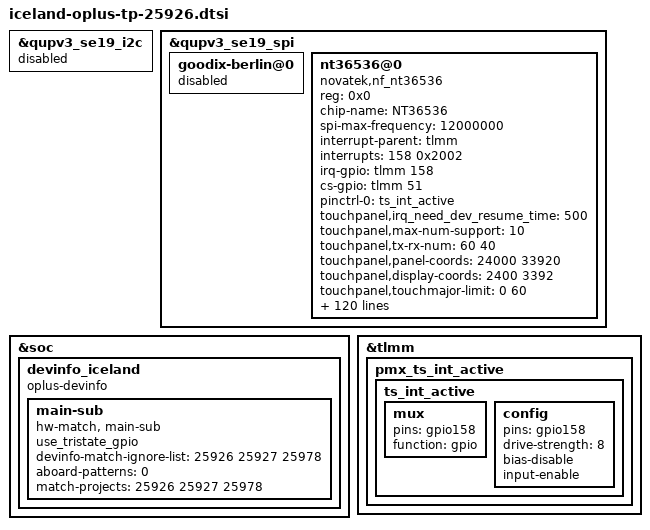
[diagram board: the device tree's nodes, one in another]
#include <dt-bindings/clock/qcom,gcc-sun.h>
#include <dt-bindings/clock/qcom,rpmh.h>
#include "iceland-oplus-tp_firmware_nt36536.dtsi"

&qupv3_se19_i2c {
	status = "disabled";
};
/*
&qupv3_se19_spi{
	/delete-property/ pinctrl-0;
	/delete-property/ pinctrl-1;
 	pinctrl-0 = <&qupv3_se19_spi_mosi_active>, <&qupv3_se19_spi_miso_active>,
 				<&qupv3_se19_spi_clk_active>, <&qupv3_se19_spi_cs_active>;
 	pinctrl-1 = <&qupv3_se19_spi_sleep>, <&qupv3_se19_spi_cs_sleep>;
 };
*/
&qupv3_se19_spi {
	status = "ok";

	goodix-berlin@0 {
		status = "disabled";
	};

	nt36536@0 {
		status = "ok";
		compatible = "novatek,nf_nt36536";
		reg = <0x0>;
		chip-name = "NT36536";
		spi-max-frequency = <12000000>; //4800000,9600000,15000000,19200000

		/* Interrupt && Irq-gpio */
		interrupt-parent = <&tlmm>;
		interrupts = <158 0x2002>;

		/* Other HW Resource */
		irq-gpio = <&tlmm 158 0x2002>;
		/* reset-gpio = <&tlmm 98 0x00>; */
		cs-gpio = <&tlmm 51 0x00>;
		pinctrl-names = "default";
		pinctrl-0 = <&ts_int_active>;

		touchpanel,irq_need_dev_resume_time = <500>;
		touchpanel,max-num-support = <10>;
		touchpanel,tx-rx-num = <60 40>;
		touchpanel,panel-coords = <24000 33920>;
		touchpanel,display-coords = <2400 3392>;
		touchpanel,touchmajor-limit = <0 60>;
		touchpanel,single-optimized-time = <8>;

		touchpanel,pen-tx-rx-num = <12 8>;
		touchpanel,doze-tx-num = <12>;
		touchpanel,pen-panel-coords = <24000 33920>;
		touchpanel,pen-max-pressure = <16384>;
		touchpanel,other-pencil-pressure = <3 4096>;
		touchpanel,pen_max_diff = <14500>;
		touchpanel,pen-max-tilt = <60 60>;
		touchpanel,msecs-to-jiffies-time = <100>;
		touchpanel,smooth-level = <255 32 64 96 128 254>;
		touchpanel,sensitive-level = <255 20 15 12 10 5>;
		touchpanel,sensitive-level-charging = <255 30 20 15 12 7>;

		panel_type = <15>;
		// type of tp_dev ,TP-HUAXING = 15;
		firmware_name = "0x2XN251CN00";
		platform_support_project = <25926 25927 25978>;
		platform_support_project_dir = <25926 25926 25926>;
		platform_support_project_commandline = "default_commandline";
		prevention,curved_screen_V2;
		prevention,grip_disable_level = <6>;
		prevention,updelay_time_ms = <30>;
		prevention,makeup_cnt_weight = <5 1 2 2 2>;
		prevention,large_corner_range = <1200 3000>;
		prevention,large_corner_judge_condition = <500 100 1000 7 7>;
		prevention,trx_reject_condition = <10 8 8>;
		prevention,trx_strict_reject_condition = <13 7 7>;
		prevention,large_judge_time_ms = <550 50 100>;
		prevention,large_exit_condition = <6 6 7>;
		prevention,single_channel_width = <320 320>;
		prevention,normal_tap_condition = <10 350>;
		prevention,long_edge_condition = <200 150 60 80>;
		prevention,long_strict_edge_condition = <130 70>;
		prevention,long_fingerhold_condition = <70 6 4 4>;
		prevention,short_edge_condition = <150 100 80 60>;
		prevention,short_strict_edge_condition = <130 70>;
		prevention,large_strict_exit_condition = <2 2>;
		prevention,top_corner_config = <500 1500 300>;
		prevention,edge_swipe_config = <300 1400>;

		prevention,curved_screen_V4;
		prevention,long_eliminate_point_type = <2 24000 11306 300 28000 300 1>;
		prevention,long_fingerhold_condition2 = <650 2000 0 0>;
		prevention,top_corner_config2 = <3 80 600 1500 0>;
		prevention,hor_long_top_corner_config = <350 2270 0 0>;
		prevention,top_middle_config = <24000 300 1000 1>;
		prevention,corner_eliminate_point_type = <0 1380 2280 1>;
		prevention,finger_hold_differ_size = <1 0 300 300>;
		prevention,finger_hold_max_rx_exit_distance = <5 350 2300>;
		prevention,max_rx_exit_distance = <1 5 150 350 2000>;
		prevention,dynamic_finger_hold_exit_distance = <1 350 2300 450>;
		prevention,large_corner_judge_condition_ime = <300 0 0 0 0>;

		prevention,curved_screen_v4_3;
		prevention,corner_point_edge_percent_thd = <900 1 25 32 1>;
		prevention,corner_point_edge_percent_thd2 = <50 3 20 1400 0>;
		prevention,point_stability_judgment_check = <2 2 10 0 0>;
		prevention,point_corner_er_min_limit_check = <3 3 0 0 1>;
		prevention,one_frame_down_check_support = <1>;
		prevention,uniform_make_up_point_v2 = <10 2 45 5 1>;

		prevention,touch_point_stability_check = <100 500 0 0 0>;
		prevention,middle_bottom_long_press_check = <6 140 10 0 1>;
		prevention,middle_bottom_small_press_check = <4 70 550 140 10>;
		prevention,middle_bottom_exit_dis = <600 450 20 450 0>;
		prevention,middle_bottom_yfsr_coupling_thd = <80 55 5 12 0>;

		prevention,curved_screen_v4_5;
		prevention,long_press_corner_point_edge_percent_thd = <1200 1600 1 1 28 33 200 1>;
		prevention,center_down_corner_point_edge_percent_thd = <2500 1800 1 1 45 37 0 1>;
		prevention,soon_meet_corner_point_edge_percent_thd = <1600 2000 1 1 35 40 2 1>;


		incell_screen;
		//iovcc_shutdown_support;
		kernel_grip_support;
		tx_rx_num_exchange_support;
		black_gesture_support;
		charger_pump_support;
		esd_handle_support;
		black_gesture_test_support;
		game_switch_support;
		aiunit_game_info_support;
		game_enable_in_tddi_support;
		noflash_support;
		lcd_trigger_load_tp_fw_support;
		smart_gesture_support;
		pressure_report_support;
		touchz_to_pressure_support;
		pen_support;
		pen_support_opp;
		// waterproof_support;
		irq_need_dev_resume_ok;
		fw_update_app_support;
		health_monitor_support;
		fw_update_in_probe_with_headfile;
		black_gesture_indep_support;
		report_rate_limit;
		tp_scene_para_switch_support;
		exception_upload_support;
		input_timestamp_in_top_irq_support;
		tp_data_record_support;

		/*
		 *Virtual Key Config:
		 *1:touchpanel,button-type: <virtualkey_type  supportted_button-map>
		 *virtualkey_type:
		 *Type 1: using board_properties
		 *Type 2: using same IC (button zone&& touch zone are seprate)
		 *Type 3: using diffrent IC (button zone&& touch zone are seprate)
		 *Type 4: No need of virtual key process
		 *supportted_button-map:select|menu|home|back
		 *
		 *2:touchpanel,button-map
		 *type (X1,Y1)(X2,Y2)(X3,Y3)(Width_X,Hight_Y)--Only when button-type is 0
		 */
		touchpanel,button-type = <4>;
		touchpanel.button-TRx = <0 0>;
	};
};

&soc {
	devinfo_iceland {
		compatible = "oplus-devinfo";

		main-sub {
			use_tristate_gpio;
			devinfo-match-ignore-list = <25926 25927 25978>;
			compatible = "hw-match, main-sub";
			aboard-patterns = <0>;	/*0[high-resistance] 1[pull-down] 2[pull-up]*/
			/*main board*/
			match-projects = <25926 25927 25978>;
		};
	};
};

&tlmm {
 	pmx_ts_int_active {
 		ts_int_active: ts_int_active {
 			mux {
 				pins = "gpio158";
 				function = "gpio";
 			};

 			config {
 				pins = "gpio158";
 				drive-strength = <8>;
 				bias-disable;
 				input-enable;
 			};
 		};
 	};
/*
	qupv3_se19_spi_pins: qupv3_se19_spi_pins {
		qupv3_se19_spi_miso_active: qupv3_se19_spi_miso_active {
			mux {
				pins = "gpio48";
				function = "qup4_se0_l0";
			};

			config {
				pins = "gpio48";
				drive-strength = <4>;
				bias-disable;
			};
		};

		qupv3_se19_spi_mosi_active: qupv3_se19_spi_mosi_active {
			mux {
				pins = "gpio49";
				function = "qup4_se0_l1";
			};

			config {
				pins = "gpio49";
				drive-strength = <4>;
				bias-disable;
			};
		};

		qupv3_se19_spi_clk_active: qupv3_se19_spi_clk_active {
			mux {
				pins = "gpio50";
				function = "qup4_se0_l2";
			};

			config {
				pins = "gpio50";
				drive-strength = <4>;
				bias-disable;
			};
		};

		qupv3_se19_spi_cs_active: qupv3_se19_spi_cs_active {
			mux {
				pins = "gpio51";
				function = "qup4_se0_l3";
			};

			config {
				pins = "gpio51";
				drive-strength = <4>;
				bias-disable;
			};
		};

		qupv3_se19_spi_sleep: qupv3_se19_spi_sleep {
			mux {
				pins = "gpio48", "gpio49",
					"gpio50";
				function = "gpio";
			};

			config {
				pins = "gpio48", "gpio49",
					"gpio50";
				drive-strength = <2>;
				bias-disable;
			};
		};

		qupv3_se19_spi_cs_sleep: qupv3_se19_spi_cs_sleep {
			mux {
				pins = "gpio51";
				function = "gpio";
			};

			config {
				pins = "gpio51";
				drive-strength = <2>;
				bias-disable;
				output-high;
			};
		};
	};
*/
};

